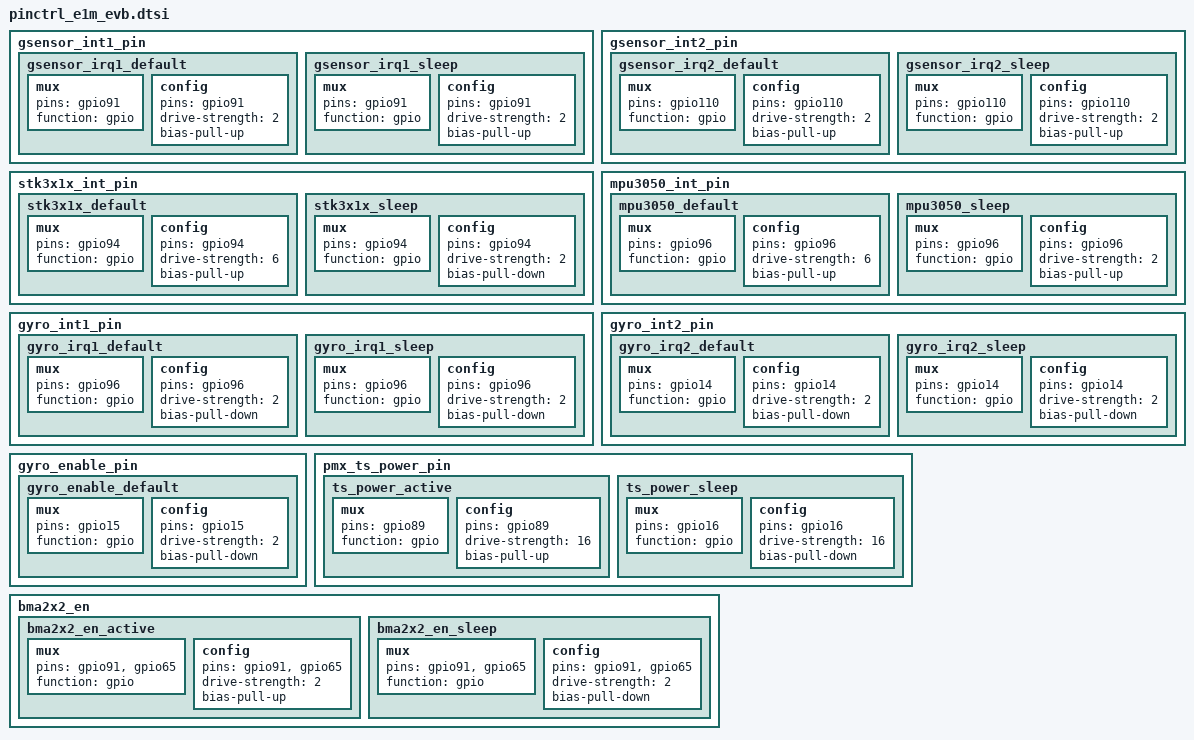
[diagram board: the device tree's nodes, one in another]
//Gsensor STM-LIS3DSHTR PINCTRL, BEGIN
//GS_INT1
		gsensor_int1_pin {
			gsensor_irq1_default: gsensor_irq1_default {
				mux {
					pins = "gpio91";
					function = "gpio";
				};

				config {
					pins = "gpio91";
					drive-strength = <2>;
					bias-pull-up;
				};
			};

			gsensor_irq1_sleep: gsensor_irq1_sleep {
				mux {
					pins = "gpio91";
					function = "gpio";
				};

				config {
					pins = "gpio91";
					drive-strength = <2>;
					bias-pull-up;
				};
			};
		};
    
//GS_INT2
		gsensor_int2_pin {
			gsensor_irq2_default: gsensor_irq2_default {
				mux {
					pins = "gpio110";
					function = "gpio";
				};

				config {
					pins = "gpio110";
					drive-strength = <2>;
					bias-pull-up;
				};
			};

			gsensor_irq2_sleep: gsensor_irq2_sleep {
				mux {
					pins = "gpio110";
					function = "gpio";
				};

				config {
					pins = "gpio110";
					drive-strength = <2>;
					bias-pull-up;
				};
			};
		};

//Gsensor STM-LIS3DSHTR PINCTRL, END

//ALS-PS STK3x1x PINCTRL, START
		stk3x1x_int_pin {
			stk3x1x_default: stk3x1x_default {
				mux {
					pins = "gpio94";
					function = "gpio";
				};

				config {
					pins = "gpio94";
					drive-strength = <6>;
					bias-pull-up;
				};
			};

			stk3x1x_sleep: stk3x1x_sleep {
				mux {
					pins = "gpio94";
					function = "gpio";
				};

				config {
					pins = "gpio94";
					drive-strength = <2>;
					bias-pull-down;
				};
			};
		};


//ALS-PS STK3x1x PINCTRL, END

//Gyro MPU3050 PINCTRL, START
		mpu3050_int_pin {
			mpu3050_default: mpu3050_default {
				mux {
					pins = "gpio96";
					function = "gpio";
				};

				config {
					pins = "gpio96";
					drive-strength = <6>;
					bias-pull-up;
				};
			};

			mpu3050_sleep: mpu3050_sleep {
				mux {
					pins = "gpio96";
					function = "gpio";
				};

				config {
					pins = "gpio96";
					drive-strength = <2>;
					bias-pull-up;
				};
			};
		};


//Gyro MPU3050 PINCTRL, END

//Gyro L3GD20 PINCTRL, START
		gyro_int1_pin {
			gyro_irq1_default: gyro_irq1_default {
				mux {
					pins = "gpio96";
					function = "gpio";
				};

				config {
					pins = "gpio96";
					drive-strength = <2>;
					bias-pull-down;
				};
			};

			gyro_irq1_sleep: gyro_irq1_sleep {
				mux {
					pins = "gpio96";
					function = "gpio";
				};

				config {
					pins = "gpio96";
					drive-strength = <2>;
					bias-pull-down;
				};
			};
		};

		gyro_int2_pin {
			gyro_irq2_default: gyro_irq2_default {
				mux {
					pins = "gpio14";
					function = "gpio";
				};

				config {
					pins = "gpio14";
					drive-strength = <2>;
					bias-pull-down;
				};
			};

			gyro_irq2_sleep: gyro_irq2_sleep {
				mux {
					pins = "gpio14";
					function = "gpio";
				};

				config {
					pins = "gpio14";
					drive-strength = <2>;
					bias-pull-down;
				};
			};
		};

		gyro_enable_pin {
			gyro_enable_default: gyro_enable_default {
				mux {
					pins = "gpio15";
					function = "gpio";
				};

				config {
					pins = "gpio15";
					drive-strength = <2>;
					bias-pull-down;
				};
			};
		};			
//Gyro L3GD20 PINCTRL, END


//Touch S2716 PINCTRL, BEGIN
		pmx_ts_power_pin {
			ts_power_active: ts_power_active {
				mux {
					pins = "gpio89";
					function = "gpio";
				};

				config {
					pins = "gpio89";
					drive-strength = <16>;
					bias-pull-up;
				};
			};

			ts_power_sleep: ts_power_sleep {
				mux {
					pins = "gpio16";
					function = "gpio";
				};

				config {
					pins = "gpio16";
					drive-strength = <16>;
					bias-pull-down;
				};
			};
		};

//Touch S2716 PINCTRL, END

//BMA2x2
//BMA2x2

		bma2x2_en {
			bma2x2_en_active: bma2x2_en_active {
				mux {
					pins = "gpio91", "gpio65";
					function = "gpio";
				};

				config {
					pins = "gpio91", "gpio65";
					drive-strength = <2>;
					bias-pull-up;
				};
			};

			bma2x2_en_sleep: bma2x2_en_sleep {
				mux {
					pins = "gpio91", "gpio65";
					function = "gpio";
				};

				config {
					pins = "gpio91", "gpio65";
					drive-strength = <2>;
					bias-pull-down;
				};
			};
		};

